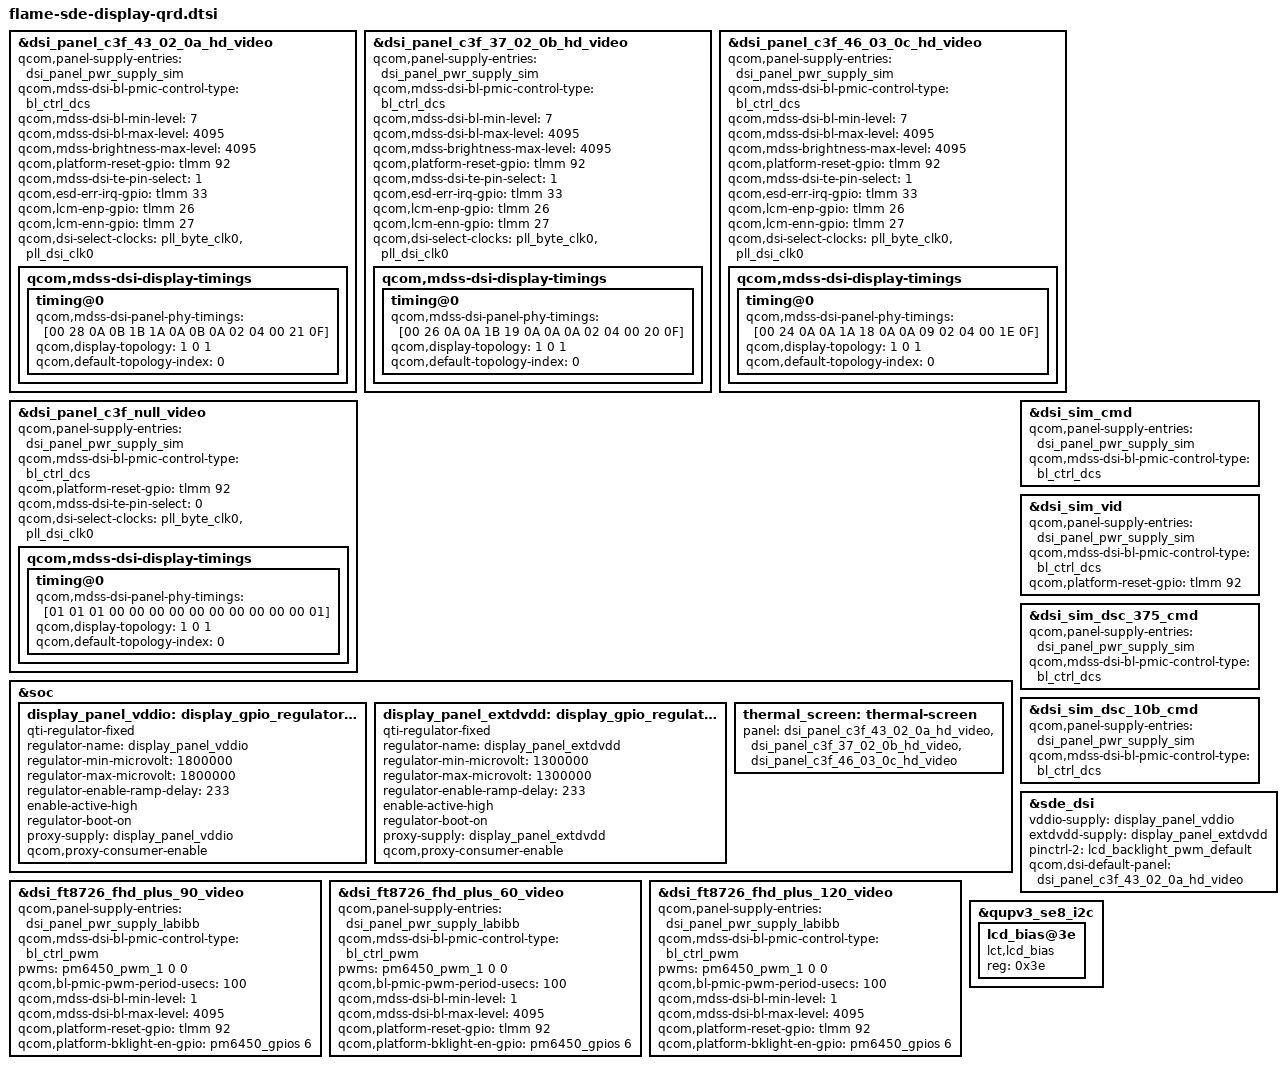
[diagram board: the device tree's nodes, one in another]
#include "touchscreen_c3f.dtsi"
#include "ravelin-sde-display.dtsi"
#include "dsi_panel_c3f_43_02_0a_hd_video.dtsi"
#include "dsi_panel_c3f_37_02_0b_hd_video.dtsi"
#include "dsi_panel_c3f_46_03_0c_hd_video.dtsi"
#include "dsi_panel_c3f_null_video.dtsi"

/*
&pmi632_lcdb {
	status = "ok";
};
&pmi632_gpios {

	display_panel_supply_ctrl {
		display_panel_vddio_default: display_panel_vddio_default {
			pins = "gpio5";
			function = "normal";
			input-disable;
			output-enable;
			bias-disable;
			drive-push-pull;
			power-source = <0>;
			qcom,drive-strength = <2>;
		};

		display_panel_extdvdd_default: display_panel_extdvdd_default {
			pins = "gpio6";
			function = "normal";
			input-disable;
			output-enable;
			bias-disable;
			power-source = <0>;
			qcom,drive-strength = <2>;
		};
	};
};
*/

&dsi_panel_c3f_43_02_0a_hd_video {
	qcom,panel-supply-entries = <&dsi_panel_pwr_supply_sim>;
	qcom,mdss-dsi-bl-pmic-control-type = "bl_ctrl_dcs";
	qcom,mdss-dsi-bl-min-level = <7>;
	qcom,mdss-dsi-bl-max-level = <4095>;
	qcom,mdss-brightness-max-level = <4095>;
	qcom,platform-reset-gpio = <&tlmm 92 0>;
	qcom,mdss-dsi-te-pin-select = <1>;
	qcom,esd-err-irq-gpio = <&tlmm 33 0x2002>;
	qcom,lcm-enp-gpio = <&tlmm 26 0>;
	qcom,lcm-enn-gpio = <&tlmm 27 0>;
	qcom,dsi-select-clocks = "pll_byte_clk0", "pll_dsi_clk0";
	qcom,mdss-dsi-display-timings {
		timing@0 {
			qcom,mdss-dsi-panel-phy-timings = [00 28 0A 0B 1B 1A 0A
				0B 0A 02 04 00 21 0F];
			qcom,display-topology = <1 0 1>;
			qcom,default-topology-index = <0>;
		};
	};
};

&dsi_panel_c3f_37_02_0b_hd_video {
	qcom,panel-supply-entries = <&dsi_panel_pwr_supply_sim>;
	qcom,mdss-dsi-bl-pmic-control-type = "bl_ctrl_dcs";
	qcom,mdss-dsi-bl-min-level = <7>;
	qcom,mdss-dsi-bl-max-level = <4095>;
	qcom,mdss-brightness-max-level = <4095>;
	qcom,platform-reset-gpio = <&tlmm 92 0>;
	qcom,mdss-dsi-te-pin-select = <1>;
	qcom,esd-err-irq-gpio = <&tlmm 33 0x2002>;
	qcom,lcm-enp-gpio = <&tlmm 26 0>;
	qcom,lcm-enn-gpio = <&tlmm 27 0>;
	qcom,dsi-select-clocks = "pll_byte_clk0", "pll_dsi_clk0";
	qcom,mdss-dsi-display-timings {
		timing@0 {
			qcom,mdss-dsi-panel-phy-timings = [00 26 0A 0A 1B 19 0A
				0A 0A 02 04 00 20 0F];
			qcom,display-topology = <1 0 1>;
			qcom,default-topology-index = <0>;
		};
	};
};

&dsi_panel_c3f_46_03_0c_hd_video {
	qcom,panel-supply-entries = <&dsi_panel_pwr_supply_sim>;
	qcom,mdss-dsi-bl-pmic-control-type = "bl_ctrl_dcs";
	qcom,mdss-dsi-bl-min-level = <7>;
	qcom,mdss-dsi-bl-max-level = <4095>;
	qcom,mdss-brightness-max-level = <4095>;
	qcom,platform-reset-gpio = <&tlmm 92 0>;
	qcom,mdss-dsi-te-pin-select = <1>;
	qcom,esd-err-irq-gpio = <&tlmm 33 0x2002>;
	qcom,lcm-enp-gpio = <&tlmm 26 0>;
	qcom,lcm-enn-gpio = <&tlmm 27 0>;
	qcom,dsi-select-clocks = "pll_byte_clk0", "pll_dsi_clk0";
	qcom,mdss-dsi-display-timings {
		timing@0 {
			qcom,mdss-dsi-panel-phy-timings = [00 24 0A 0A 1A 18 0A
				0A 09 02 04 00 1E 0F];
			qcom,display-topology = <1 0 1>;
			qcom,default-topology-index = <0>;
		};
	};
};

&dsi_panel_c3f_null_video {
	qcom,panel-supply-entries = <&dsi_panel_pwr_supply_sim>;
	qcom,mdss-dsi-bl-pmic-control-type = "bl_ctrl_dcs";
	qcom,platform-reset-gpio = <&tlmm 92 0>;
	qcom,mdss-dsi-te-pin-select = <0>;
	qcom,dsi-select-clocks = "pll_byte_clk0", "pll_dsi_clk0";
	qcom,mdss-dsi-display-timings {
		timing@0 {
			qcom,mdss-dsi-panel-phy-timings = [01 01 01 00 00 00 00
				00 00 00 00 00 00 01];
			qcom,display-topology = <1 0 1>;
			qcom,default-topology-index = <0>;
		};
	};
};

&soc {
	display_panel_vddio: display_gpio_regulator@1 {
		compatible = "qti-regulator-fixed";
		regulator-name = "display_panel_vddio";
		regulator-min-microvolt = <1800000>;
		regulator-max-microvolt = <1800000>;
		regulator-enable-ramp-delay = <233>;
//		gpio = <&pmi632_gpios 5 0>;
		enable-active-high;
		regulator-boot-on;
		proxy-supply = <&display_panel_vddio>;
		qcom,proxy-consumer-enable;
//		pinctrl-names = "default";
//		pinctrl-0 = <&display_panel_vddio_default>;
	};

	display_panel_extdvdd: display_gpio_regulator@2 {
		compatible = "qti-regulator-fixed";
		regulator-name = "display_panel_extdvdd";
		regulator-min-microvolt = <1300000>;
		regulator-max-microvolt = <1300000>;
		regulator-enable-ramp-delay = <233>;
//		gpio = <&pmi632_gpios 6 0>;
		enable-active-high;
		regulator-boot-on;
		proxy-supply = <&display_panel_extdvdd>;
		qcom,proxy-consumer-enable;
//		pinctrl-names = "default";
//		pinctrl-0 = <&display_panel_extdvdd_default>;
	};

	thermal_screen: thermal-screen {
		panel = <&dsi_panel_c3f_43_02_0a_hd_video &dsi_panel_c3f_37_02_0b_hd_video &dsi_panel_c3f_46_03_0c_hd_video>;
	};

};

&dsi_ft8726_fhd_plus_90_video {
	qcom,panel-supply-entries = <&dsi_panel_pwr_supply_labibb>;
	qcom,mdss-dsi-bl-pmic-control-type = "bl_ctrl_pwm";
	pwms = <&pm6450_pwm_1 0 0>;
	qcom,bl-pmic-pwm-period-usecs = <100>;
	qcom,mdss-dsi-bl-min-level = <1>;
	qcom,mdss-dsi-bl-max-level = <4095>;
	qcom,platform-reset-gpio = <&tlmm 92 0>;
	qcom,platform-bklight-en-gpio = <&pm6450_gpios 6 0>;
};

&dsi_ft8726_fhd_plus_60_video {
	qcom,panel-supply-entries = <&dsi_panel_pwr_supply_labibb>;
	qcom,mdss-dsi-bl-pmic-control-type = "bl_ctrl_pwm";
	pwms = <&pm6450_pwm_1 0 0>;
	qcom,bl-pmic-pwm-period-usecs = <100>;
	qcom,mdss-dsi-bl-min-level = <1>;
	qcom,mdss-dsi-bl-max-level = <4095>;
	qcom,platform-reset-gpio = <&tlmm 92 0>;
	qcom,platform-bklight-en-gpio = <&pm6450_gpios 6 0>;
};

&dsi_ft8726_fhd_plus_120_video {
	qcom,panel-supply-entries = <&dsi_panel_pwr_supply_labibb>;
	qcom,mdss-dsi-bl-pmic-control-type = "bl_ctrl_pwm";
	pwms = <&pm6450_pwm_1 0 0>;
	qcom,bl-pmic-pwm-period-usecs = <100>;
	qcom,mdss-dsi-bl-min-level = <1>;
	qcom,mdss-dsi-bl-max-level = <4095>;
	qcom,platform-reset-gpio = <&tlmm 92 0>;
	qcom,platform-bklight-en-gpio = <&pm6450_gpios 6 0>;
};

&dsi_sim_cmd {
	qcom,panel-supply-entries = <&dsi_panel_pwr_supply_sim>;
	qcom,mdss-dsi-bl-pmic-control-type = "bl_ctrl_dcs";
};

&dsi_sim_vid {
	qcom,panel-supply-entries = <&dsi_panel_pwr_supply_sim>;
	qcom,mdss-dsi-bl-pmic-control-type = "bl_ctrl_dcs";
	qcom,platform-reset-gpio = <&tlmm 92 0>;
};

&dsi_sim_dsc_375_cmd {
	qcom,panel-supply-entries = <&dsi_panel_pwr_supply_sim>;
	qcom,mdss-dsi-bl-pmic-control-type = "bl_ctrl_dcs";
};

&dsi_sim_dsc_10b_cmd {
	qcom,panel-supply-entries = <&dsi_panel_pwr_supply_sim>;
	qcom,mdss-dsi-bl-pmic-control-type = "bl_ctrl_dcs";
};

&sde_dsi {
	//lab-supply = <&lcdb_ldo_vreg>;
	//ibb-supply = <&lcdb_ncp_vreg>;

	vddio-supply = <&display_panel_vddio>;
	extdvdd-supply = <&display_panel_extdvdd>;

	pinctrl-names = "panel_active", "panel_suspend", "pwm_pin";
	pinctrl-2 = <&lcd_backlight_pwm_default>;

	qcom,dsi-default-panel = <&dsi_panel_c3f_43_02_0a_hd_video>;
};

&qupv3_se8_i2c{
	status = "okay";
	lcd_bias@3e {
        compatible = "lct,lcd_bias";
		reg = <0x3e>;
	};
};

/*
&qupv3_se1_i2c {
	focaltech@38 {
		panel = <&dsi_ft8726_fhd_plus_120_video
			&dsi_ft8726_fhd_plus_90_video
			&dsi_ft8726_fhd_plus_60_video>;
	};
};
*/
